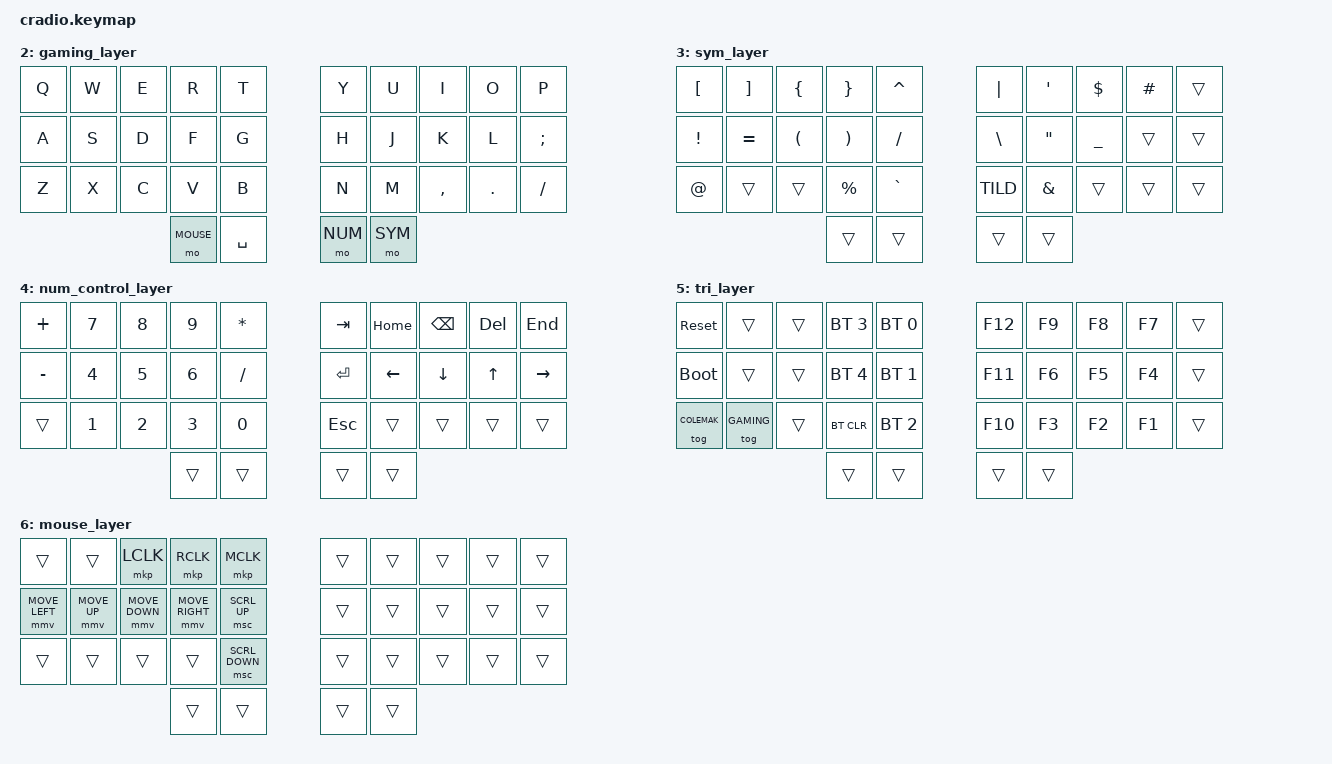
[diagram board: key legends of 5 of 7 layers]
// Copyright (c) 2022 The ZMK Contributors
// SPDX-License-Identifier: MIT

#include <behaviors.dtsi>
#include <dt-bindings/zmk/keys.h>
#include <dt-bindings/zmk/bt.h>
#include <dt-bindings/zmk/pointing.h>

// Home row mods macro
#define HRML(k1,k2,k3,k4) &lht LALT k1  &ht LGUI k2   &ht LCTRL k3 &sht LSHFT k4  
#define HRMR(k1,k2,k3,k4) &sht RSHFT k1  &ht RCTRL k2  &ht RGUI k3  &lht RALT k4

#define DEFAULT 0
#define COLEMAK 1
#define GAMING 2
#define SYM 3
#define NUM 4
#define TRI 5
#define MOUSE 6

/ {
    behaviors {
        sht: short_hold_tap {
            compatible = "zmk,behavior-hold-tap";
            #binding-cells = <2>;
            flavor = "tap-preferred";
            tapping-term-ms = <160>;
            require-prior-idle-ms = <90>;
            bindings = <&kp>, <&kp>;
        };
        ht: hold_tap {
            compatible = "zmk,behavior-hold-tap";
            #binding-cells = <2>;
            flavor = "tap-preferred";
            tapping-term-ms = <200>;
            require-prior-idle-ms = <200>;
            bindings = <&kp>, <&kp>;
        };
        lht: long_hold_tap {
            compatible = "zmk,behavior-hold-tap";
            #binding-cells = <2>;
            flavor = "tap-preferred";
            tapping-term-ms = <300>;
            require-prior-idle-ms = <200>;
            bindings = <&kp>, <&kp>;
        };

        conditional_layers {
            compatible = "zmk,conditional-layers";
            tri_layer {
                if-layers = <SYM NUM>;
                then-layer = <TRI>;
            };
        };
    };

    combos {
        compatible = "zmk,combos";
        combo_caps_word {
            timeout-ms = <50>;
            key-positions = <20 29>;
            bindings = <&caps_word>;
        };

        combo_caps_lock {
            timeout-ms = <50>;
            key-positions = <24 25>;
            bindings = <&kp CAPS>;
        };
    };

    keymap {
        compatible = "zmk,keymap";
        default_layer {
            bindings = <
        //╭──────────┬──────────┬──────────┬──────────┬──────────╮   ╭──────────┬──────────┬──────────┬──────────┬──────────╮
        //│  Q       │  W       │  E       │  R       │  T       │   │  Y       │  U       │  I       │  O       │  P       │
            &kp Q      &kp W      &kp E      &kp R      &kp T          &kp Y      &kp U      &kp I      &kp O      &kp P
        //├──────────┼──────────┼──────────┼──────────┼──────────┤   ├──────────┼──────────┼──────────┼──────────┼──────────┤
        //│  A       │  S       │  D       │  F       │  G       │   │  H       │  J       │  K       │  L       │ ; :      │
            HRML(A,       S,        D,          F)      &kp G          &kp H      HRMR(J,        K,         L,       SEMI)
        //├──────────┼──────────┼──────────┼──────────┼──────────┤   ├──────────┼──────────┼──────────┼──────────┼──────────┤
        //│  Z       │  X       │  C       │  V       │  B       │   │  N       │  M       │ , <      │ . >      │ / ?      │
            &kp Z      &kp X      &kp C      &kp V      &kp B          &kp N      &kp M      &kp COMMA  &kp DOT    &kp FSLH
        //╰──────────┴──────────┴──────────┼──────────┼──────────┤   ├──────────┼──────────┼──────────┴──────────┴──────────╯
                                            &mo MOUSE   &kp SPACE     &mo NUM     &mo SYM
        //                                 ╰──────────┴──────────╯   ╰──────────┴──────────╯
            >;
        };

        colemak_layer { // for older windows machines without colemak keyboard option
            bindings = <
        //╭──────────┬──────────┬──────────┬──────────┬──────────╮   ╭──────────┬──────────┬──────────┬──────────┬──────────╮
        //│  Q       │  W       │  F       │  P       │  G       │   │  J       │  L       │  U       │  Y       │  ; :     │
            &kp Q      &kp W      &kp F      &kp P      &kp G          &kp J      &kp L      &kp U      &kp Y      &kp SEMI
        //├──────────┼──────────┼──────────┼──────────┼──────────┤   ├──────────┼──────────┼──────────┼──────────┼──────────┤
        //│  A       │  R       │  S       │  T       │  D       │   │  H       │  N       │  E       │  I       │ O        │
            HRML(A,       R,        S,          T)      &kp D          &kp H      HRMR(N,        E,         I,       O)
        //├──────────┼──────────┼──────────┼──────────┼──────────┤   ├──────────┼──────────┼──────────┼──────────┼──────────┤
        //│  Z       │  X       │  C       │  V       │  B       │   │  K       │  M       │ , <      │ . >      │ / ?      │
            &kp Z      &kp X      &kp C      &kp V      &kp B          &kp K      &kp M      &kp COMMA  &kp DOT    &kp FSLH
        //╰──────────┴──────────┴──────────┼──────────┼──────────┤   ├──────────┼──────────┼──────────┴──────────┴──────────╯
                                            &mo MOUSE   &kp SPACE     &mo NUM     &mo SYM
        //                                 ╰──────────┴──────────╯   ╰──────────┴──────────╯
            >;
        };

        gaming_layer {
            bindings = <
        //╭──────────┬──────────┬──────────┬──────────┬──────────╮   ╭──────────┬──────────┬──────────┬──────────┬──────────╮
        //│  Q       │  W       │  E       │  R       │  T       │   │  Y       │  U       │  I       │  O       │  P       │
            &kp Q      &kp W      &kp E      &kp R      &kp T          &kp Y      &kp U      &kp I      &kp O      &kp P
        //├──────────┼──────────┼──────────┼──────────┼──────────┤   ├──────────┼──────────┼──────────┼──────────┼──────────┤
        //│  A       │  S       │  D       │  F       │  G       │   │  H       │  J       │  K       │  L       │ ; :      │
            &kp A      &kp S      &kp D      &kp F      &kp G          &kp H      &kp J      &kp K      &kp L      &kp SEMI
        //├──────────┼──────────┼──────────┼──────────┼──────────┤   ├──────────┼──────────┼──────────┼──────────┼──────────┤
        //│  Z       │  X       │  C       │  V       │  B       │   │  N       │  M       │ , <      │ . >      │ / ?      │
            &kp Z      &kp X      &kp C      &kp V      &kp B          &kp N      &kp M      &kp COMMA  &kp DOT    &kp FSLH
        //╰──────────┴──────────┴──────────┼──────────┼──────────┤   ├──────────┼──────────┼──────────┴──────────┴──────────╯
                                            &mo MOUSE   &kp SPACE     &mo NUM     &mo SYM
        //                                 ╰──────────┴──────────╯   ╰──────────┴──────────╯
            >;
        };

        sym_layer {
            bindings = <
        //╭──────────┬──────────┬──────────┬──────────┬──────────╮   ╭──────────┬──────────┬──────────┬──────────┬──────────╮
        //│ [        │  ]       │  {       │  }       │ ^        │   │ |        │ '        │ $        │ #        │          │
            &kp LBKT   &kp RBKT   &kp LBRC   &kp RBRC   &kp CARET      &kp PIPE   &kp APOS  &kp DLLR    &kp HASH    &trans
        //├──────────┼──────────┼──────────┼──────────┼──────────┤   ├──────────┼──────────┼──────────┼──────────┼──────────┤
        //│ !        │  =       │  (       │  )       │ /        │   │ \        │ "        │  _       │          │          │
            &kp EXCL  &kp EQUAL  &kp LPAR    &kp RPAR   &kp FSLH       &kp BSLH   &kp DQT   &kp UNDER    &trans     &trans
        //├──────────┼──────────┼──────────┼──────────┼──────────┤   ├──────────┼──────────┼──────────┼──────────┼──────────┤
        //│ @        │          │          │  %       │  `       │   │ ~        │ &        │          │          │          │
           &kp AT      &trans     &trans     &kp PRCNT  &kp GRAVE      &kp TILD   &kp AMPS    &trans     &trans     &trans
        //╰──────────┴──────────┴──────────┼──────────┼──────────┤   ├──────────┼──────────┼──────────┴──────────┴──────────╯
                                             &trans     &trans         &trans     &trans
        //                                 ╰──────────┴──────────╯   ╰──────────┴──────────╯
            >;
        };

        num_control_layer {
            bindings = <
        //╭──────────┬──────────┬──────────┬──────────┬──────────╮   ╭──────────┬──────────┬──────────┬──────────┬──────────╮
        //│  +       │  7       │  8       │  9       │  *       │   │  TAB     │  HOME    │  BKSP    │  DEL     │  END     │
            &kp PLUS   &kp    N7  &kp    N8 &kp    N9   &kp STAR      &kp TAB    &kp HOME   &kp BSPC   &kp DEL    &kp END
        //├──────────┼──────────┼──────────┼──────────┼──────────┤   ├──────────┼──────────┼──────────┼──────────┼──────────┤
        //│  -       │  4       │  5       │  6       │  /       │   │  ENTER   │  LEFT    │  DOWN    │  UP      │  RIGHT   │
            &kp MINUS  &kp    N4 &kp    N5  &kp    N6   &kp FSLH      &kp ENTER  &kp LEFT   &kp DOWN  &kp UP      &kp RIGHT
        //├──────────┼──────────┼──────────┼──────────┼──────────┤   ├──────────┼──────────┼──────────┼──────────┼──────────┤
        //│          │ 1        │ 2        │ 3        │ 0        │   │  ESC     │          │          │          │          │
            &trans     &kp    N1  &kp    N2  &kp    N3  &kp    N0      &kp ESC    &trans     &trans      &trans    &trans
        //╰──────────┴──────────┴──────────┼──────────┼──────────┤   ├──────────┼──────────┼──────────┴──────────┴──────────╯
                                             &trans     &trans         &trans     &trans
        //                                 ╰──────────┴──────────╯   ╰──────────┴──────────╯
            >;
        };

        tri_layer {
            bindings = <
        //╭──────────┬──────────┬──────────┬──────────┬──────────╮   ╭──────────┬──────────┬──────────┬──────────┬──────────╮
        //│ RESET    │          │          │PROFILE 3 │PROFILE 0 │   │          │          │          │          │          │
           &sys_reset  &trans     &trans   &bt BT_SEL 3 &bt BT_SEL 0   &kp F12    &kp F9     &kp F8     &kp F7     &trans
        //├──────────┼──────────┼──────────┼──────────┼──────────┤   ├──────────┼──────────┼──────────┼──────────┼──────────┤
        //│BOOTLOADER│          │          │PROFILE 4 │PROFILE 1 │   │          │          │          │          │          │
          &bootloader  &trans     &trans   &bt BT_SEL 4 &bt BT_SEL 1   &kp F11    &kp F6     &kp F5     &kp F4     &trans
        //├──────────┼──────────┼──────────┼──────────┼──────────┤   ├──────────┼──────────┼──────────┼──────────┼──────────┤
        //│          │          │          │ CLEAR BT │PROFILE 2 │   │          │          │          │          │          │
          &tog COLEMAK &tog GAMING &trans  &bt BT_CLR   &bt BT_SEL 2   &kp F10    &kp F3     &kp F2     &kp F1     &trans
        //╰──────────┴──────────┴──────────┼──────────┼──────────┤   ├──────────┼──────────┼──────────┴──────────┴──────────╯
                                             &trans     &trans         &trans     &trans
        //                                 ╰──────────┴──────────╯   ╰──────────┴──────────╯
            >;
        };

        mouse_layer {
            bindings = <
        //╭──────────┬──────────┬──────────┬──────────┬──────────╮   ╭──────────┬──────────┬──────────┬──────────┬──────────╮
        //│          │          │          │          │          │   │          │          │          │          │          │
           &trans      &trans    &mkp LCLK  &mkp RCLK  &mkp MCLK       &trans     &trans     &trans     &trans    &trans
        //├──────────┼──────────┼──────────┼──────────┼──────────┤   ├──────────┼──────────┼──────────┼──────────┼──────────┤
        //│          │          │          │          │          │   │          │          │          │          │          │
           &mmv MOVE_LEFT &mmv MOVE_UP &mmv MOVE_DOWN &mmv MOVE_RIGHT &msc SCRL_UP    &trans     &trans     &trans     &trans    &trans
        //├──────────┼──────────┼──────────┼──────────┼──────────┤   ├──────────┼──────────┼──────────┼──────────┼──────────┤
        //│          │          │          │          │          │   │          │          │          │          │          │
            &trans     &trans     &trans    &trans     &msc SCRL_DOWN  &trans     &trans     &trans     &trans     &trans
        //╰──────────┴──────────┴──────────┼──────────┼──────────┤   ├──────────┼──────────┼──────────┴──────────┴──────────╯
                                             &trans     &trans         &trans     &trans
        //                                 ╰──────────┴──────────╯   ╰──────────┴──────────╯
            >;
        };
    };
};
